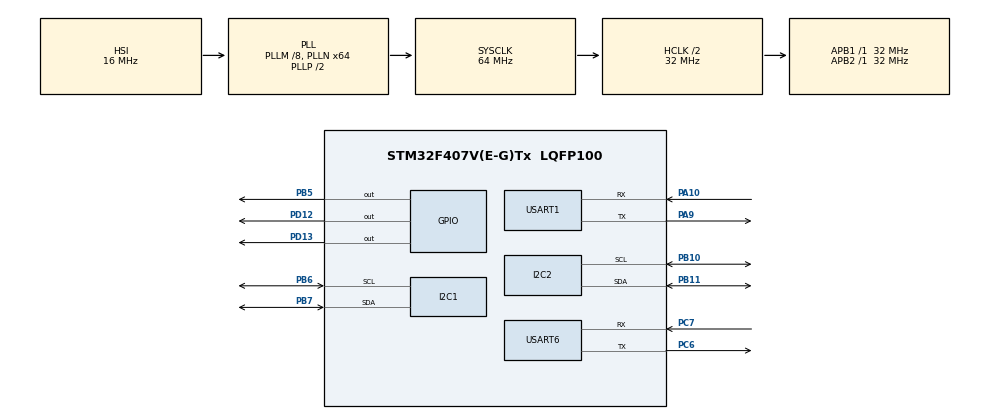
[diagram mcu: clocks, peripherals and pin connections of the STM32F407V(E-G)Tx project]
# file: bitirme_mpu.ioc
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I2C1.I2C_Mode=I2C_Fast
I2C2.I2C_Mode=I2C_Fast
Mcu.Family=STM32F4
Mcu.Name=STM32F407V(E-G)Tx
Mcu.Package=LQFP100
NVIC.PriorityGroup=NVIC_PRIORITYGROUP_4
PA10.Mode=Asynchronous
PA10.Signal=USART1_RX
PA13.Mode=Serial_Wire
PA13.Signal=SYS_JTMS-SWDIO
PA14.Mode=Serial_Wire
PA14.Signal=SYS_JTCK-SWCLK
PA9.Mode=Asynchronous
PA9.Signal=USART1_TX
PB10.Mode=I2C
PB10.Signal=I2C2_SCL
PB11.Mode=I2C
PB11.Signal=I2C2_SDA
PB5.Signal=GPIO_Output
PB6.Mode=I2C
PB6.Signal=I2C1_SCL
PB7.Mode=I2C
PB7.Signal=I2C1_SDA
PC6.Mode=Asynchronous
PC6.Signal=USART6_TX
PC7.Mode=Asynchronous
PC7.Signal=USART6_RX
PD12.Signal=GPIO_Output
PD13.Signal=GPIO_Output
PH0-OSC_IN.Mode=HSE-External-Oscillator
PH0-OSC_IN.Signal=RCC_OSC_IN
PH1-OSC_OUT.Mode=HSE-External-Oscillator
PH1-OSC_OUT.Signal=RCC_OSC_OUT
ProjectManager.HeapSize=0x200
ProjectManager.StackSize=0x400
ProjectManager.TargetToolchain=STM32CubeIDE
RCC.48MHZClocksFreq_Value=32000000
RCC.AHBCLKDivider=RCC_SYSCLK_DIV2
RCC.AHBFreq_Value=32000000
RCC.APB1Freq_Value=32000000
RCC.APB1TimFreq_Value=32000000
RCC.APB2Freq_Value=32000000
RCC.APB2TimFreq_Value=32000000
RCC.CortexFreq_Value=32000000
RCC.HCLKFreq_Value=32000000
RCC.HSE_VALUE=25000000
RCC.HSI_VALUE=16000000
RCC.LSE_VALUE=32768
RCC.PLLM=8
RCC.PLLN=64
RCC.SYSCLKFreq_VALUE=64000000
RCC.SYSCLKSource=RCC_SYSCLKSOURCE_PLLCLK
RCC.VCOOutputFreq_Value=128000000
TIM3.Period=1
TIM3.Prescaler=15999
TIM3.TIM_MasterOutputTrigger=TIM_TRGO_UPDATE
USART1.VirtualMode=VM_ASYNC
USART6.VirtualMode=VM_ASYNC
VP_TIM3_VS_ClockSourceINT.Mode=Internal
board=custom

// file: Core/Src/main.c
/* USER CODE BEGIN Header */
/**
  ******************************************************************************
  * @file           : main.c
  * @brief          : Main program body
  ******************************************************************************
  * @attention
  *
  * Copyright (c) 2023 STMicroelectronics.
  * All rights reserved.
  *
  * This software is licensed under terms that can be found in the LICENSE file
  * in the root directory of this software component.
  * If no LICENSE file comes with this software, it is provided AS-IS.
  *
  ******************************************************************************
  */
/* USER CODE END Header */
#include "main.h"

/* USER CODE BEGIN Includes */
#include "mpu6050.h"
/* USER CODE END Includes */

I2C_HandleTypeDef hi2c1;
I2C_HandleTypeDef hi2c2;

TIM_HandleTypeDef htim3;

UART_HandleTypeDef huart1;
UART_HandleTypeDef huart6;

void SystemClock_Config(void);
static void MX_GPIO_Init(void);
static void MX_I2C1_Init(void);
static void MX_USART1_UART_Init(void);
static void MX_I2C2_Init(void);
static void MX_USART6_UART_Init(void);
static void MX_TIM3_Init(void);

int main(void)
{

  /* MCU Configuration--------------------------------------------------------*/

  /* Reset of all peripherals, Initializes the Flash interface and the Systick. */
  HAL_Init();

  /* Configure the system clock */
  SystemClock_Config();

  /* Initialize all configured peripherals */
  MX_GPIO_Init();
  MX_I2C1_Init();
  MX_USART1_UART_Init();
  MX_I2C2_Init();
  MX_USART6_UART_Init();
  MX_TIM3_Init();
  /* USER CODE BEGIN 2 */
  HAL_TIM_Base_Start_IT(&htim3);
  MPU6050Config();
  MPU6050GyroAverage();

  /* USER CODE END 2 */

  /* Infinite loop */
  while (1)
  {

    /* USER CODE BEGIN 3 */
  MPU6050AccelRead();

  }
  /* USER CODE END 3 */
}

void SystemClock_Config(void)
{
  RCC_OscInitTypeDef RCC_OscInitStruct = {0};
  RCC_ClkInitTypeDef RCC_ClkInitStruct = {0};

  /** Configure the main internal regulator output voltage
  */
  __HAL_RCC_PWR_CLK_ENABLE();
  __HAL_PWR_VOLTAGESCALING_CONFIG(PWR_REGULATOR_VOLTAGE_SCALE1);

  /** Initializes the RCC Oscillators according to the specified parameters
  * in the RCC_OscInitTypeDef structure.
  */
  RCC_OscInitStruct.OscillatorType = RCC_OSCILLATORTYPE_HSI;
  RCC_OscInitStruct.HSIState = RCC_HSI_ON;
  RCC_OscInitStruct.HSICalibrationValue = RCC_HSICALIBRATION_DEFAULT;
  RCC_OscInitStruct.PLL.PLLState = RCC_PLL_ON;
  RCC_OscInitStruct.PLL.PLLSource = RCC_PLLSOURCE_HSI;
  RCC_OscInitStruct.PLL.PLLM = 8;
  RCC_OscInitStruct.PLL.PLLN = 64;
  RCC_OscInitStruct.PLL.PLLP = RCC_PLLP_DIV2;
  RCC_OscInitStruct.PLL.PLLQ = 4;
  if (HAL_RCC_OscConfig(&RCC_OscInitStruct) != HAL_OK)
  {
    Error_Handler();
  }

  /** Initializes the CPU, AHB and APB buses clocks
  */
  RCC_ClkInitStruct.ClockType = RCC_CLOCKTYPE_HCLK|RCC_CLOCKTYPE_SYSCLK
                              |RCC_CLOCKTYPE_PCLK1|RCC_CLOCKTYPE_PCLK2;
  RCC_ClkInitStruct.SYSCLKSource = RCC_SYSCLKSOURCE_PLLCLK;
  RCC_ClkInitStruct.AHBCLKDivider = RCC_SYSCLK_DIV2;
  RCC_ClkInitStruct.APB1CLKDivider = RCC_HCLK_DIV1;
  RCC_ClkInitStruct.APB2CLKDivider = RCC_HCLK_DIV1;

  if (HAL_RCC_ClockConfig(&RCC_ClkInitStruct, FLASH_LATENCY_1) != HAL_OK)
  {
    Error_Handler();
  }
}

static void MX_I2C1_Init(void)
{

  hi2c1.Instance = I2C1;
  hi2c1.Init.ClockSpeed = 400000;
  hi2c1.Init.DutyCycle = I2C_DUTYCYCLE_2;
  hi2c1.Init.OwnAddress1 = 0;
  hi2c1.Init.AddressingMode = I2C_ADDRESSINGMODE_7BIT;
  hi2c1.Init.DualAddressMode = I2C_DUALADDRESS_DISABLE;
  hi2c1.Init.OwnAddress2 = 0;
  hi2c1.Init.GeneralCallMode = I2C_GENERALCALL_DISABLE;
  hi2c1.Init.NoStretchMode = I2C_NOSTRETCH_DISABLE;
  if (HAL_I2C_Init(&hi2c1) != HAL_OK)
  {
    Error_Handler();
  }

}

static void MX_I2C2_Init(void)
{

  hi2c2.Instance = I2C2;
  hi2c2.Init.ClockSpeed = 400000;
  hi2c2.Init.DutyCycle = I2C_DUTYCYCLE_2;
  hi2c2.Init.OwnAddress1 = 0;
  hi2c2.Init.AddressingMode = I2C_ADDRESSINGMODE_7BIT;
  hi2c2.Init.DualAddressMode = I2C_DUALADDRESS_DISABLE;
  hi2c2.Init.OwnAddress2 = 0;
  hi2c2.Init.GeneralCallMode = I2C_GENERALCALL_DISABLE;
  hi2c2.Init.NoStretchMode = I2C_NOSTRETCH_DISABLE;
  if (HAL_I2C_Init(&hi2c2) != HAL_OK)
  {
    Error_Handler();
  }

}

static void MX_TIM3_Init(void)
{

  TIM_ClockConfigTypeDef sClockSourceConfig = {0};
  TIM_MasterConfigTypeDef sMasterConfig = {0};

  htim3.Instance = TIM3;
  htim3.Init.Prescaler = 15999;
  htim3.Init.CounterMode = TIM_COUNTERMODE_UP;
  htim3.Init.Period = 1;
  htim3.Init.ClockDivision = TIM_CLOCKDIVISION_DIV1;
  htim3.Init.AutoReloadPreload = TIM_AUTORELOAD_PRELOAD_DISABLE;
  if (HAL_TIM_Base_Init(&htim3) != HAL_OK)
  {
    Error_Handler();
  }
  sClockSourceConfig.ClockSource = TIM_CLOCKSOURCE_INTERNAL;
  if (HAL_TIM_ConfigClockSource(&htim3, &sClockSourceConfig) != HAL_OK)
  {
    Error_Handler();
  }
  sMasterConfig.MasterOutputTrigger = TIM_TRGO_UPDATE;
  sMasterConfig.MasterSlaveMode = TIM_MASTERSLAVEMODE_DISABLE;
  if (HAL_TIMEx_MasterConfigSynchronization(&htim3, &sMasterConfig) != HAL_OK)
  {
    Error_Handler();
  }

}

static void MX_USART1_UART_Init(void)
{

  huart1.Instance = USART1;
  huart1.Init.BaudRate = 115200;
  huart1.Init.WordLength = UART_WORDLENGTH_8B;
  huart1.Init.StopBits = UART_STOPBITS_1;
  huart1.Init.Parity = UART_PARITY_NONE;
  huart1.Init.Mode = UART_MODE_TX_RX;
  huart1.Init.HwFlowCtl = UART_HWCONTROL_NONE;
  huart1.Init.OverSampling = UART_OVERSAMPLING_16;
  if (HAL_UART_Init(&huart1) != HAL_OK)
  {
    Error_Handler();
  }

}

static void MX_USART6_UART_Init(void)
{

  huart6.Instance = USART6;
  huart6.Init.BaudRate = 115200;
  huart6.Init.WordLength = UART_WORDLENGTH_8B;
  huart6.Init.StopBits = UART_STOPBITS_1;
  huart6.Init.Parity = UART_PARITY_NONE;
  huart6.Init.Mode = UART_MODE_TX_RX;
  huart6.Init.HwFlowCtl = UART_HWCONTROL_NONE;
  huart6.Init.OverSampling = UART_OVERSAMPLING_16;
  if (HAL_UART_Init(&huart6) != HAL_OK)
  {
    Error_Handler();
  }

}

static void MX_GPIO_Init(void)
{
  GPIO_InitTypeDef GPIO_InitStruct = {0};

  /* GPIO Ports Clock Enable */
  __HAL_RCC_GPIOH_CLK_ENABLE();
  __HAL_RCC_GPIOB_CLK_ENABLE();
  __HAL_RCC_GPIOD_CLK_ENABLE();
  __HAL_RCC_GPIOC_CLK_ENABLE();
  __HAL_RCC_GPIOA_CLK_ENABLE();

  /*Configure GPIO pin Output Level */
  HAL_GPIO_WritePin(GPIOD, GPIO_PIN_12|GPIO_PIN_13, GPIO_PIN_RESET);

  /*Configure GPIO pin Output Level */
  HAL_GPIO_WritePin(GPIOB, GPIO_PIN_5, GPIO_PIN_RESET);

  /*Configure GPIO pins : PD12 PD13 */
  GPIO_InitStruct.Pin = GPIO_PIN_12|GPIO_PIN_13;
  GPIO_InitStruct.Mode = GPIO_MODE_OUTPUT_PP;
  GPIO_InitStruct.Pull = GPIO_NOPULL;
  GPIO_InitStruct.Speed = GPIO_SPEED_FREQ_LOW;
  HAL_GPIO_Init(GPIOD, &GPIO_InitStruct);

  /*Configure GPIO pin : PB5 */
  GPIO_InitStruct.Pin = GPIO_PIN_5;
  GPIO_InitStruct.Mode = GPIO_MODE_OUTPUT_PP;
  GPIO_InitStruct.Pull = GPIO_NOPULL;
  GPIO_InitStruct.Speed = GPIO_SPEED_FREQ_LOW;
  HAL_GPIO_Init(GPIOB, &GPIO_InitStruct);

}

void Error_Handler(void)
{
  __disable_irq();
  while (1)
  {
  }
}
